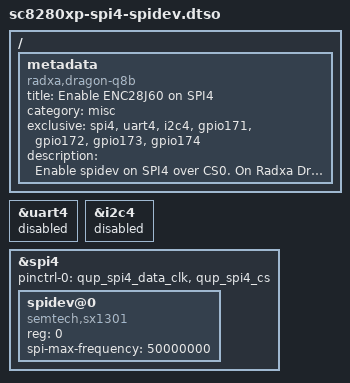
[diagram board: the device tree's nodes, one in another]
// SPDX-License-Identifier: BSD-3-Clause
/*
 * Copyright (c) 2026 Radxa Computer (Shenzhen) Co., Ltd.
 */

/dts-v1/;
/plugin/;

/ {
	metadata {
		title = "Enable ENC28J60 on SPI4";
		compatible = "radxa,dragon-q8b";
		category = "misc";
		exclusive = "spi4", "uart4", "i2c4", "gpio171", "gpio172", "gpio173", "gpio174";
		description = "Enable spidev on SPI4 over CS0.
On Radxa Dragon Q8B, this is pin 35(miso), 38(mosi), 40(sclk), 12(cs0).";
	};
};

&uart4 {
	status = "disabled";
};

&i2c4 {
	status = "disabled";
};

&spi4 {
	pinctrl-0 = <&qup_spi4_data_clk>, <&qup_spi4_cs>;
	pinctrl-names = "default";
	
	status = "okay";
	
	spidev@0 {
		compatible = "semtech,sx1301";
		status = "okay";
		reg = <0>;
		spi-max-frequency = <50000000>;
	};
};
